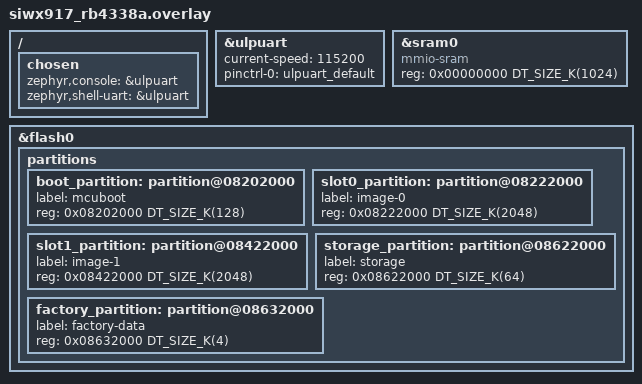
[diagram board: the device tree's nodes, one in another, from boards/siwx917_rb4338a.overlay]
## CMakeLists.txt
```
#
# Copyright (c) 2023-2024 Project CHIP Authors
#
# Licensed under the Apache License, Version 2.0 (the "License");
# you may not use this file except in compliance with the License.
# You may obtain a copy of the License at
#
# http://www.apache.org/licenses/LICENSE-2.0
#
# Unless required by applicable law or agreed to in writing, software
# distributed under the License is distributed on an "AS IS" BASIS,
# WITHOUT WARRANTIES OR CONDITIONS OF ANY KIND, either express or implied.
# See the License for the specific language governing permissions and
# limitations under the License.
#
cmake_minimum_required(VERSION 3.13.1)

get_filename_component(CHIP_ROOT ${CMAKE_CURRENT_SOURCE_DIR}/third_party/connectedhomeip REALPATH)
get_filename_component(GEN_DIR ${CHIP_ROOT}/zzz_generated/ REALPATH)
get_filename_component(SILABS_PLATFORM_COMMON ${CHIP_ROOT}/examples/platform/silabs REALPATH)
get_filename_component(SILABS_LIGHTING_COMMON ${CHIP_ROOT}/examples/lighting-app/silabs REALPATH)
get_filename_component(ALL_CLUSTERS_COMMON_DIR ${CHIP_ROOT}/examples/all-clusters-app/all-clusters-common REALPATH)
#get_filename_component(EXAMPLE_PLATFORM_SILABS_COMMON_DIR ${CHIP_ROOT}/examples/platform/nxp/common REALPATH)
#get_filename_component(EXAMPLE_PLATFORM_SILABS_ZEPHYR_DIR ${CHIP_ROOT}/examples/platform/nxp/zephyr REALPATH)

list(APPEND ZEPHYR_EXTRA_MODULES ${CHIP_ROOT}/config/silabs)
find_package(Zephyr HINTS $ENV{ZEPHYR_BASE})

# -Wmaybe-uninitialized has too many false positives, including on std::optional
# and chip::Optional.  Make it nonfatal.
#
# See https://gcc.gnu.org/bugzilla/show_bug.cgi?id=80635
target_compile_options(app PRIVATE -Werror -Wno-error=maybe-uninitialized)
target_compile_options(app PRIVATE -Werror PRIVATE -Wno-error=format)

project(matter-silabs-light)

include(${CHIP_ROOT}/config/silabs/app/enable-gnu-std.cmake)
include(${CHIP_ROOT}/src/app/chip_data_model.cmake)

target_include_directories(app
    PRIVATE
    include
    ${LAUNDRY_WASHER_SILABS_COMMON_DIR}/Zephyr/include
    ${ALL_CLUSTERS_COMMON_DIR}/include
    ${GEN_DIR}/app-common
    ${GEN_DIR}/all-clusters-app
    ${EXAMPLE_PLATFORM_SILABS_COMMON_DIR}/device_manager/include
    ${EXAMPLE_PLATFORM_SILABS_COMMON_DIR}/icd/include
    ${EXAMPLE_PLATFORM_SILABS_COMMON_DIR}/device_callbacks/include
    ${EXAMPLE_PLATFORM_SILABS_COMMON_DIR}/factory_data/include
    ${EXAMPLE_PLATFORM_SILABS_COMMON_DIR}/app_task/include
)

target_sources(app
    PRIVATE
    ${SILABS_PLATFORM_COMMON}/zephyr/src/main.cpp
    # ${LAUNDRY_WASHER_SILABS_COMMON_DIR}/main/AppTask.cpp
    # ${EXAMPLE_PLATFORM_SILABS_COMMON_DIR}/device_manager/source/CHIPDeviceManager.cpp
    # ${LAUNDRY_WASHER_SILABS_COMMON_DIR}/main/DeviceCallbacks.cpp
    # ${EXAMPLE_PLATFORM_SILABS_COMMON_DIR}/device_callbacks/source/CommonDeviceCallbacks.cpp
    # ${LAUNDRY_WASHER_SILABS_COMMON_DIR}/main/ZclCallbacks.cpp
    # ${ALL_CLUSTERS_COMMON_DIR}/src/binding-handler.cpp
    # ${EXAMPLE_PLATFORM_SILABS_COMMON_DIR}/app_task/source/AppTaskBase.cpp
    # ${EXAMPLE_PLATFORM_SILABS_COMMON_DIR}/app_task/source/AppTaskZephyr.cpp
    # ${EXAMPLE_PLATFORM_SILABS_ZEPHYR_DIR}/factory_data/source/AppFactoryDataExample.cpp
)

target_compile_definitions(app PUBLIC
    "EXTERNAL_FACTORY_DATA_PROVIDER_IMPL_HEADER=\"platform/nxp/zephyr/FactoryDataProviderImpl.h\""
)

# TODO MATTER-4291
if(CONFIG_CHIP_OTA_REQUESTOR)
    # target_sources(app PRIVATE
    #                 ${EXAMPLE_PLATFORM_SILABS_COMMON_DIR}/ota_requestor/source/OTARequestorInitiatorCommon.cpp
    #                 ${EXAMPLE_PLATFORM_SILABS_COMMON_DIR}/ota_requestor/source/OTARequestorInitiatorZephyr.cpp
    # )
    # target_include_directories(app PRIVATE
    #                 ${EXAMPLE_PLATFORM_SILABS_COMMON_DIR}/ota_requestor/include/
    # )
endif()

if(CONFIG_CHIP_WIFI)
  chip_configure_data_model(app
      ZAP_FILE ${SILABS_LIGHTING_COMMON}/data_model/lighting-wifi-app.zap
  )
else()
  chip_configure_data_model(app
      ZAP_FILE ${SILABS_LIGHTING_COMMON}/data_model/lighting-thread-app.zap
  )
endif()

if(CONFIG_CHIP_LIB_SHELL)
    target_compile_definitions(app PRIVATE ENABLE_CHIP_SHELL)
    target_include_directories(app PRIVATE 
                               ${CHIP_ROOT}/examples/shell/shell_common/include
                               ${EXAMPLE_PLATFORM_SILABS_COMMON_DIR}/matter_cli/include
    )
    target_sources(app PRIVATE
                   ${EXAMPLE_PLATFORM_SILABS_COMMON_DIR}/matter_cli/source/AppCLIBase.cpp
                   ${EXAMPLE_PLATFORM_SILABS_COMMON_DIR}/matter_cli/source/AppCLIZephyr.cpp
                   ${CHIP_ROOT}/examples/shell/shell_common/cmd_misc.cpp
                   ${CHIP_ROOT}/examples/shell/shell_common/cmd_otcli.cpp
                   ${CHIP_ROOT}/examples/shell/shell_common/cmd_server.cpp
    )
endif()

# TODO MATTER-4291
# target_sources(app
#     PRIVATE
#     ${ALL_CLUSTERS_COMMON_DIR}/src/smco-stub.cpp
#     ${ALL_CLUSTERS_COMMON_DIR}/src/bridged-actions-stub.cpp
#     # ${ALL_CLUSTERS_COMMON_DIR}/src/static-supported-temperature-levels.cpp
#     # ${ALL_CLUSTERS_COMMON_DIR}/src/laundry-washer-controls-delegate-impl.cpp
#     # ${ALL_CLUSTERS_COMMON_DIR}/src/operational-state-delegate-impl.cpp
# )
```

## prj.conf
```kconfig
#
#    Copyright (c) 2022 Project CHIP Authors
#
#    Licensed under the Apache License, Version 2.0 (the "License");
#    you may not use this file except in compliance with the License.
#    You may obtain a copy of the License at
#
#        http://www.apache.org/licenses/LICENSE-2.0
#
#    Unless required by applicable law or agreed to in writing, software
#    distributed under the License is distributed on an "AS IS" BASIS,
#    WITHOUT WARRANTIES OR CONDITIONS OF ANY KIND, either express or implied.
#    See the License for the specific language governing permissions and
#    limitations under the License.
#

# This sample uses Kconfig.defaults to set options common for all
# samples. This file should contain only options specific for this sample
# or overrides of default values.

# Enable CHIP
CONFIG_CHIP=y
CONFIG_CHIP_PROJECT_CONFIG="include/CHIPProjectConfig.h"
# 32773 == 0x8005 (example lighting-app)
CONFIG_CHIP_DEVICE_PRODUCT_ID=32773
CONFIG_STD_CPP17=y

CONFIG_GPIO=y

# Enable Matter extended announcement and increase duration to 1 hour.
CONFIG_CHIP_BLE_EXT_ADVERTISING=y
CONFIG_CHIP_BLE_ADVERTISING_DURATION=60

# Add support for LEDs and buttons on Nordic development kits
# Add support for LEDs and buttons on Silabs development kits
# TODO MATTER-4291
#CONFIG_PWM=y
# Add support for LCD on Silabs development kits
# General networking settings
CONFIG_NET_IF_MCAST_IPV6_ADDR_COUNT=5

# Bluetooth Low Energy configuration
CONFIG_BT_DEVICE_NAME="MatterLight"


# Other settings
CONFIG_THREAD_NAME=y

# Reduce application size
CONFIG_USE_SEGGER_RTT=n
```

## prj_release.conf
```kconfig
#
#    Copyright (c) 2022 Project CHIP Authors
#
#    Licensed under the Apache License, Version 2.0 (the "License");
#    you may not use this file except in compliance with the License.
#    You may obtain a copy of the License at
#
#        http://www.apache.org/licenses/LICENSE-2.0
#
#    Unless required by applicable law or agreed to in writing, software
#    distributed under the License is distributed on an "AS IS" BASIS,
#    WITHOUT WARRANTIES OR CONDITIONS OF ANY KIND, either express or implied.
#    See the License for the specific language governing permissions and
#    limitations under the License.
#

# This sample uses Kconfig.defaults to set options common for all
# samples. This file should contain only options specific for this sample
# or overrides of default values.

# Enable CHIP
CONFIG_CHIP=y
CONFIG_CHIP_PROJECT_CONFIG="include/CHIPProjectConfig.h"
# 32773 == 0x8005 (example lighting-app)
CONFIG_CHIP_DEVICE_PRODUCT_ID=32773
CONFIG_STD_CPP17=y

# Enable Matter pairing automatically on application start.
CONFIG_CHIP_ENABLE_PAIRING_AUTOSTART=y

# Enable Matter extended announcement and increase duration to 1 hour.
CONFIG_CHIP_BLE_EXT_ADVERTISING=y
CONFIG_CHIP_BLE_ADVERTISING_DURATION=60

# Add support for LEDs and buttons on Silabs development kits
# TODO MATTER-4291
#CONFIG_PWM=y
# Add support for LCD on Silabs development kits

# General networking settings
CONFIG_NET_IF_MCAST_IPV6_ADDR_COUNT=14

# Bluetooth Low Energy configuration
CONFIG_BT_DEVICE_NAME="MatterLight"

# Stack size settings


# Disable all debug features
CONFIG_USE_SEGGER_RTT=n
CONFIG_SHELL=n
CONFIG_OPENTHREAD_SHELL=n
CONFIG_CONSOLE=n
CONFIG_UART_CONSOLE=n
CONFIG_SERIAL=n
CONFIG_LOG=n
CONFIG_LOG_MODE_MINIMAL=n
CONFIG_ASSERT_VERBOSE=n
CONFIG_ASSERT_NO_FILE_INFO=y
CONFIG_PRINTK=n
CONFIG_PRINTK_SYNC=n
CONFIG_BOOT_BANNER=n
```

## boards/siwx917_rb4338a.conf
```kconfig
#
#    Copyright (c) 2024 Project CHIP Authors
#
#    Licensed under the Apache License, Version 2.0 (the "License");
#    you may not use this file except in compliance with the License.
#    You may obtain a copy of the License at
#
#        http://www.apache.org/licenses/LICENSE-2.0
#
#    Unless required by applicable law or agreed to in writing, software
#    distributed under the License is distributed on an "AS IS" BASIS,
#    WITHOUT WARRANTIES OR CONDITIONS OF ANY KIND, either express or implied.
#    See the License for the specific language governing permissions and
#    limitations under the License.
#
```

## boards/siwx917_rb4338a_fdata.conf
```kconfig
#
#    Copyright (c) 2024 Project CHIP Authors
#
#    Licensed under the Apache License, Version 2.0 (the "License");
#    you may not use this file except in compliance with the License.
#    You may obtain a copy of the License at
#
#        http://www.apache.org/licenses/LICENSE-2.0
#
#    Unless required by applicable law or agreed to in writing, software
#    distributed under the License is distributed on an "AS IS" BASIS,
#    WITHOUT WARRANTIES OR CONDITIONS OF ANY KIND, either express or implied.
#    See the License for the specific language governing permissions and
#    limitations under the License.
#

# 0xA226
CONFIG_CHIP_DEVICE_PRODUCT_ID=41510 # TODO MATTER-4864
CONFIG_CHIP_DEVICE_PRODUCT_URL="tbd"
CONFIG_CHIP_DEVICE_PRODUCT_LABEL="siwg917"
CONFIG_CHIP_DEVICE_PART_NUMBER="siwg917"
```

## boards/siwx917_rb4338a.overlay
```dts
/*
 *    Copyright (c) 2024 Project CHIP Authors
 *    All rights reserved.
 *
 *    Licensed under the Apache License, Version 2.0 (the "License");
 *    you may not use this file except in compliance with the License.
 *    You may obtain a copy of the License at
 *
 *        http: //www.apache.org/licenses/LICENSE-2.0
 *
 *    Unless required by applicable law or agreed to in writing, software
 *    distributed under the License is distributed on an "AS IS" BASIS
 *    WITHOUT WARRANTIES OR CONDITIONS OF ANY KIND, either express or implied.
 *    See the License for the specific language governing permissions and
 *    limitations under the License.
 */

/ {
	chosen {
		zephyr,console = &ulpuart;
		zephyr,shell-uart = &ulpuart;
	};
};

&ulpuart {
	status = "okay";
	current-speed = <115200>;
	pinctrl-0 = <&ulpuart_default>;
	pinctrl-names = "default";
};

/* Matter required multiples partition
 * 1. Bootloader for OTA
 * 2. Code partition
 * 3. Persistent storage
 * 4. Factory settings (certificate and others)
 */

&sram0 {
	status = "okay";
	compatible = "mmio-sram";
	reg = <0x00000000 DT_SIZE_K(1024)>;
};

&flash0 {
	status = "okay";
	partitions {
		boot_partition: partition@08202000 {
			label = "mcuboot";
			reg = <0x08202000 DT_SIZE_K(128)>;
		};

		slot0_partition: partition@08222000 {
			label = "image-0";
			reg = <0x08222000 DT_SIZE_K(2048)>;
		};

		slot1_partition: partition@08422000 {
			label = "image-1";
			reg = <0x08422000 DT_SIZE_K(2048)>;
		};

		storage_partition: partition@08622000 {
			label = "storage";
			reg = <0x08622000 DT_SIZE_K(64)>;
		};

		factory_partition: partition@08632000 {
			label = "factory-data";
			reg = <0x08632000 DT_SIZE_K(4)>;
		};

	};

};
```

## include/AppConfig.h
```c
/*
 *
 *    Copyright (c) 2020 Project CHIP Authors
 *    Copyright (c) 2019 Google LLC.
 *    All rights reserved.
 *
 *    Licensed under the Apache License, Version 2.0 (the "License");
 *    you may not use this file except in compliance with the License.
 *    You may obtain a copy of the License at
 *
 *        http://www.apache.org/licenses/LICENSE-2.0
 *
 *    Unless required by applicable law or agreed to in writing, software
 *    distributed under the License is distributed on an "AS IS" BASIS,
 *    WITHOUT WARRANTIES OR CONDITIONS OF ANY KIND, either express or implied.
 *    See the License for the specific language governing permissions and
 *    limitations under the License.
 */

#pragma once

#include "silabs_utils.h"

// ---- Lighting Example App Config ----

#ifdef SL_CATALOG_ZIGBEE_ZCL_FRAMEWORK_CORE_PRESENT
#include "sl_cmp_config.h"
#ifdef SL_MATTER_ZIGBEE_CMP
#include "ZigbeeCMPConfig.h"
#elif defined(SL_MATTER_ZIGBEE_SEQUENTIAL)
#include "ZigbeeSequentialConfig.h"
#endif // SL_MATTER_ZIGBEE_CMP
#else
#define APP_TASK_NAME "Light"
#define BLE_DEV_NAME "SL-" APP_TASK_NAME

#define ON_DEMO_BITMAP                                                                                                             \
    0xff, 0xff, 0xff, 0xff, 0xff, 0xff, 0xff, 0xff, 0xff, 0xff, 0xff, 0xff, 0xff, 0xff, 0xff, 0xff, 0xff, 0xff, 0xff, 0x7f, 0xfc,  \
        0xff, 0xff, 0xff, 0xff, 0xff, 0xff, 0x7f, 0xfc, 0xff, 0xff, 0xff, 0xff, 0xff, 0xff, 0x7f, 0xfc, 0xff, 0xff, 0xff, 0xff,    \
        0xff, 0xff, 0x7f, 0xfc, 0xff, 0xff, 0xff, 0xff, 0xff, 0xff, 0x7f, 0xfc, 0xff, 0xff, 0xff, 0xff, 0xff, 0xff, 0x7f, 0xfc,    \
        0xff, 0xff, 0xff, 0xff, 0xff, 0xff, 0x7f, 0xfc, 0xff, 0xff, 0xff, 0xff, 0xcf, 0xff, 0xff, 0xff, 0xff, 0xf3, 0xff, 0xff,    \
        0x8f, 0xff, 0xff, 0xff, 0xff, 0xf1, 0xff, 0xff, 0x0f, 0xff, 0xff, 0xff, 0xff, 0xf0, 0xff, 0xff, 0x1f, 0xfe, 0x07, 0xe0,    \
        0x7f, 0xf8, 0xff, 0xff, 0x3f, 0xfc, 0x00, 0x00, 0x3f, 0xfc, 0xff, 0xff, 0x7f, 0x3c, 0xe0, 0x07, 0x3c, 0xfe, 0xff, 0xff,    \
        0xff, 0x1f, 0xfe, 0x7f, 0xf8, 0xff, 0xff, 0xff, 0xff, 0x0f, 0xff, 0xff, 0xf0, 0xff, 0xff, 0xff, 0xff, 0xc7, 0xff, 0xff,    \
        0xe3, 0xff, 0xff, 0xff, 0xff, 0xe3, 0xff, 0xff, 0xc7, 0xff, 0xff, 0xff, 0xff, 0xf1, 0xff, 0xff, 0x8f, 0xff, 0xff, 0xff,    \
        0xff, 0xf1, 0xff, 0xff, 0x8f, 0xff, 0xff, 0xff, 0xff, 0xf8, 0xff, 0xff, 0x1f, 0xff, 0xff, 0xff, 0x7f, 0xfc, 0xff, 0xff,    \
        0x3f, 0xfe, 0xff, 0xff, 0x7f, 0xfc, 0xff, 0xff, 0x3f, 0xfe, 0xff, 0xff, 0x7f, 0xfc, 0xff, 0xff, 0x3f, 0xfe, 0xff, 0xff,    \
        0x7f, 0xfe, 0xff, 0xff, 0x7f, 0xfe, 0xff, 0xff, 0x3f, 0xfe, 0xff, 0xff, 0x7f, 0xfc, 0xff, 0xff, 0x3f, 0xfe, 0xff, 0xff,    \
        0x7f, 0xfc, 0xff, 0x0f, 0x38, 0xfe, 0xff, 0xff, 0x7f, 0x1c, 0xf0, 0x0f, 0x38, 0xfe, 0x03, 0xc0, 0x7f, 0x1c, 0xf0, 0x0f,    \
        0x38, 0xfe, 0x27, 0xe9, 0x7f, 0x1c, 0xf0, 0xff, 0x3f, 0xfe, 0xff, 0xff, 0x7f, 0xfc, 0xff, 0xff, 0x3f, 0xfe, 0xff, 0xff,    \
        0x7f, 0xfc, 0xff, 0xff, 0x3f, 0xfe, 0xe7, 0xe7, 0x7f, 0xfc, 0xff, 0xff, 0x7f, 0xfe, 0xef, 0xf7, 0x7f, 0xfe, 0xff, 0xff,    \
        0x7f, 0xfc, 0xef, 0xf7, 0x3f, 0xfe, 0xff, 0xff, 0xff, 0xfc, 0xef, 0xf3, 0x3f, 0xff, 0xff, 0xff, 0xff, 0xf8, 0xcf, 0xf3,    \
        0x1f, 0xff, 0xff, 0xff, 0xff, 0xf8, 0xdf, 0xfb, 0x1f, 0xff, 0xff, 0xff, 0xff, 0xf1, 0xdf, 0xfb, 0x8f, 0xff, 0xff, 0xff,    \
        0xff, 0xe3, 0x9f, 0xf9, 0xc7, 0xff, 0xff, 0xff, 0xff, 0xc3, 0x9f, 0xf9, 0xc3, 0xff, 0xff, 0xff, 0xff, 0xc7, 0x9f, 0xfd,    \
        0xe3, 0xff, 0xff, 0xff, 0xff, 0x8f, 0xbf, 0xfd, 0xf1, 0xff, 0xff, 0xff, 0xff, 0x1f, 0x3f, 0xfc, 0xf8, 0xff, 0xff, 0xff,    \
        0xff, 0x3f, 0x3e, 0x7c, 0xfc, 0xff, 0xff, 0xff, 0xff, 0x7f, 0xfc, 0x3f, 0xfe, 0xff, 0xff, 0xff, 0xff, 0x7f, 0xfc, 0x3f,    \
        0xfe, 0xff, 0xff, 0xff, 0xff, 0xff, 0xf8, 0x1f, 0xff, 0xff, 0xff, 0xff, 0xff, 0xff, 0x00, 0x00, 0xff, 0xff, 0xff, 0xff,    \
        0xff, 0xff, 0x00, 0x00, 0xff, 0xff, 0xff, 0xff, 0xff, 0xff, 0xf8, 0x1f, 0xff, 0xff, 0xff, 0xff, 0xff, 0xff, 0xf8, 0x1f,    \
        0xff, 0xff, 0xff, 0xff, 0xff, 0xff, 0xf8, 0x1f, 0xff, 0xff, 0xff, 0xff, 0xff, 0xff, 0x00, 0x00, 0xff, 0xff, 0xff, 0xff,    \
        0xff, 0xff, 0x00, 0x00, 0xff, 0xff, 0xff, 0xff, 0xff, 0xff, 0xf8, 0x1f, 0xff, 0xff, 0xff, 0xff, 0xff, 0xff, 0xf1, 0x8f,    \
        0xff, 0xff, 0xff, 0xff, 0xff, 0xff, 0x01, 0x80, 0xff, 0xff, 0xff, 0xff, 0xff, 0xff, 0x03, 0xc0, 0xff, 0xff, 0xff, 0xff,    \
        0xff, 0xff, 0x3f, 0xfc, 0xff, 0xff, 0xff, 0xff, 0xff, 0xff, 0xff, 0xff, 0xff, 0xff, 0xff, 0xff, 0xff, 0xff, 0xff, 0xff,    \
        0xff, 0xff, 0xff, 0xff, 0xff, 0xff, 0xff, 0xff, 0xff, 0xff, 0xff

#define OFF_DEMO_BITMAP                                                                                                            \
    0xff, 0xff, 0xff, 0xff, 0xff, 0xff, 0xff, 0xff, 0xff, 0xff, 0xff, 0xff, 0xff, 0xff, 0xff, 0xff, 0xff, 0xff, 0xff, 0xff, 0xff,  \
        0xff, 0xff, 0xff, 0xff, 0xff, 0xff, 0xff, 0xff, 0xff, 0xff, 0xff, 0xff, 0xff, 0xff, 0xff, 0xff, 0xff, 0xff, 0xff, 0xff,    \
        0xff, 0xff, 0xff, 0xff, 0xff, 0xff, 0xff, 0xff, 0xff, 0xff, 0xff, 0xff, 0xff, 0xff, 0xff, 0xff, 0xff, 0xff, 0xff, 0xff,    \
        0xff, 0xff, 0xff, 0xff, 0xff, 0xff, 0xff, 0xff, 0xff, 0xff, 0xff, 0xff, 0xff, 0xff, 0xff, 0xff, 0xff, 0xff, 0xff, 0xff,    \
        0xff, 0xff, 0xff, 0xff, 0xff, 0xff, 0xff, 0xff, 0xff, 0xff, 0xff, 0xff, 0xff, 0xff, 0xff, 0xff, 0xff, 0xff, 0x07, 0xe0,    \
        0xff, 0xff, 0xff, 0xff, 0xff, 0xff, 0x00, 0x00, 0xff, 0xff, 0xff, 0xff, 0xff, 0x3f, 0xe0, 0x07, 0xfc, 0xff, 0xff, 0xff,    \
        0xff, 0x1f, 0xfe, 0x7f, 0xf8, 0xff, 0xff, 0xff, 0xff, 0x0f, 0xff, 0xff, 0xf0, 0xff, 0xff, 0xff, 0xff, 0xc7, 0xff, 0xff,    \
        0xe3, 0xff, 0xff, 0xff, 0xff, 0xe3, 0xff, 0xff, 0xc7, 0xff, 0xff, 0xff, 0xff, 0xf1, 0xff, 0xff, 0x8f, 0xff, 0xff, 0xff,    \
        0xff, 0xf1, 0xff, 0xff, 0x8f, 0xff, 0xff, 0xff, 0xff, 0xf8, 0xff, 0xff, 0x1f, 0xff, 0xff, 0xff, 0x7f, 0xfc, 0xff, 0xff,    \
        0x3f, 0xfe, 0xff, 0xff, 0x7f, 0xfc, 0xff, 0xff, 0x3f, 0xfe, 0xff, 0xff, 0x7f, 0xfc, 0xff, 0xff, 0x3f, 0xfe, 0xff, 0xff,    \
        0x7f, 0xfe, 0xff, 0xff, 0x7f, 0xfe, 0xff, 0xff, 0x3f, 0xfe, 0xff, 0xff, 0x7f, 0xfc, 0xff, 0xff, 0x3f, 0xfe, 0xff, 0xff,    \
        0x7f, 0xfc, 0xff, 0xff, 0x3f, 0xfe, 0xff, 0xff, 0x7f, 0xfc, 0xff, 0xff, 0x3f, 0xfe, 0xff, 0xff, 0x7f, 0xfc, 0xff, 0xff,    \
        0x3f, 0xfe, 0xff, 0xff, 0x7f, 0xfc, 0xff, 0xff, 0x3f, 0xfe, 0xff, 0xff, 0x7f, 0xfc, 0xff, 0xff, 0x3f, 0xfe, 0xff, 0xff,    \
        0x7f, 0xfc, 0xff, 0xff, 0x3f, 0xfe, 0xff, 0xff, 0x7f, 0xfc, 0xff, 0xff, 0x7f, 0xfe, 0xff, 0xff, 0x7f, 0xfe, 0xff, 0xff,    \
        0x7f, 0xfc, 0xff, 0xff, 0x3f, 0xfe, 0xff, 0xff, 0xff, 0xfc, 0xff, 0xff, 0x3f, 0xff, 0xff, 0xff, 0xff, 0xf8, 0xff, 0xff,    \
        0x1f, 0xff, 0xff, 0xff, 0xff, 0xf8, 0xff, 0xff, 0x1f, 0xff, 0xff, 0xff, 0xff, 0xf1, 0xff, 0xff, 0x8f, 0xff, 0xff, 0xff,    \
        0xff, 0xe3, 0xff, 0xff, 0xc7, 0xff, 0xff, 0xff, 0xff, 0xc3, 0xff, 0xff, 0xc3, 0xff, 0xff, 0xff, 0xff, 0xc7, 0xff, 0xff,    \
        0xe3, 0xff, 0xff, 0xff, 0xff, 0x8f, 0xff, 0xff, 0xf1, 0xff, 0xff, 0xff, 0xff, 0x1f, 0xff, 0xff, 0xf8, 0xff, 0xff, 0xff,    \
        0xff, 0x3f, 0xfe, 0x7f, 0xfc, 0xff, 0xff, 0xff, 0xff, 0x7f, 0xfc, 0x3f, 0xfe, 0xff, 0xff, 0xff, 0xff, 0x7f, 0xfc, 0x3f,    \
        0xfe, 0xff, 0xff, 0xff, 0xff, 0xff, 0xf8, 0x1f, 0xff, 0xff, 0xff, 0xff, 0xff, 0xff, 0x00, 0x00, 0xff, 0xff, 0xff, 0xff,    \
        0xff, 0xff, 0x00, 0x00, 0xff, 0xff, 0xff, 0xff, 0xff, 0xff, 0xf8, 0x1f, 0xff, 0xff, 0xff, 0xff, 0xff, 0xff, 0xf8, 0x1f,    \
        0xff, 0xff, 0xff, 0xff, 0xff, 0xff, 0xf8, 0x1f, 0xff, 0xff, 0xff, 0xff, 0xff, 0xff, 0x00, 0x00, 0xff, 0xff, 0xff, 0xff,    \
        0xff, 0xff, 0x00, 0x00, 0xff, 0xff, 0xff, 0xff, 0xff, 0xff, 0xf8, 0x1f, 0xff, 0xff, 0xff, 0xff, 0xff, 0xff, 0xf1, 0x8f,    \
        0xff, 0xff, 0xff, 0xff, 0xff, 0xff, 0x01, 0x80, 0xff, 0xff, 0xff, 0xff, 0xff, 0xff, 0x03, 0xc0, 0xff, 0xff, 0xff, 0xff,    \
        0xff, 0xff, 0x3f, 0xfc, 0xff, 0xff, 0xff, 0xff, 0xff, 0xff, 0xff, 0xff, 0xff, 0xff, 0xff, 0xff, 0xff, 0xff, 0xff, 0xff,    \
        0xff, 0xff, 0xff, 0xff, 0xff, 0xff, 0xff, 0xff, 0xff, 0xff, 0xff
#endif // SL_CATALOG_ZIGBEE_ZCL_FRAMEWORK_CORE_PRESENT

// Time it takes in ms for the simulated actuator to move from one
// state to another.
#define ACTUATOR_MOVEMENT_PERIOD_MS 10

#define LIGHT_ENDPOINT 1

// Application-defined error codes in the CHIP_ERROR space.
#define APP_ERROR_EVENT_QUEUE_FAILED CHIP_APPLICATION_ERROR(0x01)
#define APP_ERROR_CREATE_TASK_FAILED CHIP_APPLICATION_ERROR(0x02)
#define APP_ERROR_UNHANDLED_EVENT CHIP_APPLICATION_ERROR(0x03)
#define APP_ERROR_CREATE_TIMER_FAILED CHIP_APPLICATION_ERROR(0x04)
#define APP_ERROR_START_TIMER_FAILED CHIP_APPLICATION_ERROR(0x05)
#define APP_ERROR_STOP_TIMER_FAILED CHIP_APPLICATION_ERROR(0x06)
```

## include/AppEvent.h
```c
/*
 *
 *    Copyright (c) 2020 Project CHIP Authors
 *    Copyright (c) 2018 Nest Labs, Inc.
 *    All rights reserved.
 *
 *    Licensed under the Apache License, Version 2.0 (the "License");
 *    you may not use this file except in compliance with the License.
 *    You may obtain a copy of the License at
 *
 *        http://www.apache.org/licenses/LICENSE-2.0
 *
 *    Unless required by applicable law or agreed to in writing, software
 *    distributed under the License is distributed on an "AS IS" BASIS,
 *    WITHOUT WARRANTIES OR CONDITIONS OF ANY KIND, either express or implied.
 *    See the License for the specific language governing permissions and
 *    limitations under the License.
 */

#pragma once
#if (defined(SL_MATTER_RGB_LED_ENABLED) && SL_MATTER_RGB_LED_ENABLED == 1)
#include "RGBLEDWidget.h"
#endif //(defined(SL_MATTER_RGB_LED_ENABLED) && SL_MATTER_RGB_LED_ENABLED == 1)

<<<<<<< HEAD
#ifdef DISPLAY_ENABLED
#include "lcd.h"
#endif

struct AppEvent;
typedef void (*EventHandler)(AppEvent *);
=======
#include "BaseAppEvent.h"
>>>>>>> csa/v1.4.2-branch

struct AppEvent : public BaseAppEvent
{
    enum AppEventTypes
    {
<<<<<<< HEAD
        kEventType_Button = 0,
        kEventType_LCD,
        kEventType_Timer,
        kEventType_Light,
=======
        kEventType_Light = BaseAppEvent::kEventType_Max + 1,
>>>>>>> csa/v1.4.2-branch
        kEventType_Install,
    };

    union
    {
        struct
        {
            uint8_t Action;
<<<<<<< HEAD
        } ButtonEvent;
#ifdef DISPLAY_ENABLED
        struct
        {
            SilabsLCD::Screen_e screen;
        } LCDEvent;
#endif
        struct
        {
            void * Context;
        } TimerEvent;
=======
            int32_t Actor;
            uint8_t Value;
        } LightEvent;

#if (defined(SL_MATTER_RGB_LED_ENABLED) && SL_MATTER_RGB_LED_ENABLED == 1)
>>>>>>> csa/v1.4.2-branch
        struct
        {
            uint8_t Action;
            int32_t Actor;
            RGBLEDWidget::ColorData_t Value;
        } LightControlEvent;
#endif // (defined(SL_MATTER_RGB_LED_ENABLED) && SL_MATTER_RGB_LED_ENABLED == 1)
    };
};
```

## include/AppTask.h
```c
/*
 *
 *    Copyright (c) 2020 Project CHIP Authors
 *    Copyright (c) 2019 Google LLC.
 *    All rights reserved.
 *
 *    Licensed under the Apache License, Version 2.0 (the "License");
 *    you may not use this file except in compliance with the License.
 *    You may obtain a copy of the License at
 *
 *        http://www.apache.org/licenses/LICENSE-2.0
 *
 *    Unless required by applicable law or agreed to in writing, software
 *    distributed under the License is distributed on an "AS IS" BASIS,
 *    WITHOUT WARRANTIES OR CONDITIONS OF ANY KIND, either express or implied.
 *    See the License for the specific language governing permissions and
 *    limitations under the License.
 */

#pragma once

#include "BaseApplication.h"
#include <app/ConcreteAttributePath.h>
#include <app/clusters/on-off-server/on-off-server.h>
#include <cstdint>

#include <app/persistence/DeferredAttributePersistenceProvider.h>
#include <ble/Ble.h>
#include <cmsis_os2.h>
#include <lib/core/CHIPError.h>

struct AppEvent;

#if (defined(SL_MATTER_RGB_LED_ENABLED) && SL_MATTER_RGB_LED_ENABLED == 1)
enum ColorAction_t : uint8_t
{
    COLOR_ACTION_XY = 0,
    COLOR_ACTION_HSV,
    COLOR_ACTION_CT,
};
#endif

class AppTask : public BaseApplication
{

public:
    AppTask() = default;

    static AppTask & GetAppTask();

    /**
     * @brief AppTask task main loop function
     *
     * @param pvParameter FreeRTOS task parameter
     */
    static void AppTaskMain(void * pvParameter);

    CHIP_ERROR StartAppTask();

    /**
     * @brief Event handler when a button is pressed.
     *
     * @param button    APP_LIGHT_SWITCH or APP_FUNCTION_BUTTON
     * @param btnAction SL_SIMPLE_BUTTON_PRESSED, SL_SIMPLE_BUTTON_RELEASED or SL_SIMPLE_BUTTON_DISABLED
     */
    static void ButtonEventHandler(uint8_t button, uint8_t btnAction);

    static void OnTriggerOffWithEffect(OnOffEffect * effect);

    void DMPostAttributeChangeCallback(const chip::app::ConcreteAttributePath & attributePath, uint8_t type, uint16_t size,
                                       uint8_t * value);

    static void LightActionEventHandler(AppEvent * aEvent);

    static void LightTimerEventHandler(void * timerCbArg);

    static void DummyEventHandler(AppEvent * aEvent);

#if (defined(SL_MATTER_RGB_LED_ENABLED) && SL_MATTER_RGB_LED_ENABLED == 1)
    static void LightControlEventHandler(AppEvent * aEvent);
#endif

protected:
    CHIP_ERROR AppInit() override;
    CHIP_ERROR InitLight();

    static void UpdateOnOffClusterState(intptr_t context);
    chip::app::DeferredAttributePersistenceProvider * pDeferredAttributePersister = nullptr;
};
```

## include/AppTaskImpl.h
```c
/*
 *
 *    Copyright (c) 2020 Project CHIP Authors
 *    Copyright (c) 2019 Google LLC.
 *    All rights reserved.
 *
 *    Licensed under the Apache License, Version 2.0 (the "License");
 *    you may not use this file except in compliance with the License.
 *    You may obtain a copy of the License at
 *
 *        http://www.apache.org/licenses/LICENSE-2.0
 *
 *    Unless required by applicable law or agreed to in writing, software
 *    distributed under the License is distributed on an "AS IS" BASIS,
 *    WITHOUT WARRANTIES OR CONDITIONS OF ANY KIND, either express or implied.
 *    See the License for the specific language governing permissions and
 *    limitations under the License.
 */

#pragma once

#include "AppTask.h"
#include "CRTPHelpers.h"

/**
 * @brief CRTP override layer for `AppTask`.
 *
 * Each public entry point dispatches to a corresponding `Derived::*Impl()` hook.
 * The default `*Impl()` (declared private below) forwards to `AppTask`, so
 * `Derived` only needs to override the hooks whose behavior it wants to
 * customize.
 *
 * Customer code overrides these hooks in `CustomerAppTask`; see the app README
 * ("How to Override APIs").
 *
 * @tparam Derived The CRTP derived class (`CustomerAppTask`).
 */
template <typename Derived>
class AppTaskImpl : public AppTask
{
public:
    // Initialization hooks.
    CHIP_ERROR AppInit() override { CRTP_OPTIONAL_DISPATCH(AppTaskImpl, Derived, AppInitImpl); }

    CHIP_ERROR InitLight() { CRTP_OPTIONAL_DISPATCH(AppTaskImpl, Derived, InitLightImpl); }

    // External callbacks invoked outside the AppTask thread (e.g. button ISR, OnOff cluster).
    // Implementations typically post an event to the AppTask queue.
    static void ButtonEventHandler(uint8_t button, uint8_t btnAction)
    {
        CRTP_OPTIONAL_STATIC_DISPATCH(AppTaskImpl, Derived, ButtonEventHandlerImpl, button, btnAction);
    }

    static void OnTriggerOffWithEffect(OnOffEffect * effect)
    {
        CRTP_OPTIONAL_STATIC_DISPATCH(AppTaskImpl, Derived, OnTriggerOffWithEffectImpl, effect);
    }

    // Handlers invoked from AppTask, timer, or stack threads — see each method for the exact context.
    static void LightActionEventHandler(AppEvent * aEvent)
    {
        CRTP_OPTIONAL_STATIC_DISPATCH(AppTaskImpl, Derived, LightActionEventHandlerImpl, aEvent);
    }

    static void LightTimerEventHandler(void * timerCbArg)
    {
        CRTP_OPTIONAL_STATIC_DISPATCH(AppTaskImpl, Derived, LightTimerEventHandlerImpl, timerCbArg);
    }

#if (defined(SL_MATTER_RGB_LED_ENABLED) && SL_MATTER_RGB_LED_ENABLED == 1)
    static void LightControlEventHandler(AppEvent * aEvent)
    {
        CRTP_OPTIONAL_STATIC_DISPATCH(AppTaskImpl, Derived, LightControlEventHandlerImpl, aEvent);
    }
#endif

    void DMPostAttributeChangeCallback(const chip::app::ConcreteAttributePath & attributePath, uint8_t type, uint16_t size,
                                       uint8_t * value)
    {
        CRTP_OPTIONAL_VOID_DISPATCH(AppTaskImpl, Derived, DMPostAttributeChangeCallbackImpl, attributePath, type, size, value);
    }

    static void DummyEventHandler(AppEvent * aEvent)
    {
        CRTP_OPTIONAL_STATIC_DISPATCH(AppTaskImpl, Derived, DummyEventHandlerImpl, aEvent);
    }

private:
    friend Derived;

    /** Default implementations — override in Derived to customize. */

    // Initialization hooks (*Impl)
    CHIP_ERROR AppInitImpl() { return AppTask::AppInit(); }

    CHIP_ERROR InitLightImpl() { return AppTask::InitLight(); }

    // External callbacks (*Impl)
    void ButtonEventHandlerImpl(uint8_t button, uint8_t btnAction) { AppTask::ButtonEventHandler(button, btnAction); }

    void OnTriggerOffWithEffectImpl(OnOffEffect * effect) { AppTask::OnTriggerOffWithEffect(effect); }

    // Event / timer / data-model handlers (*Impl)
    void LightActionEventHandlerImpl(AppEvent * aEvent) { AppTask::LightActionEventHandler(aEvent); }

    void LightTimerEventHandlerImpl(void * timerCbArg) { AppTask::LightTimerEventHandler(timerCbArg); }

#if (defined(SL_MATTER_RGB_LED_ENABLED) && SL_MATTER_RGB_LED_ENABLED == 1)
    void LightControlEventHandlerImpl(AppEvent * aEvent) { AppTask::LightControlEventHandler(aEvent); }
#endif

    void DMPostAttributeChangeCallbackImpl(const chip::app::ConcreteAttributePath & attributePath, uint8_t type, uint16_t size,
                                           uint8_t * value)
    {
        AppTask::DMPostAttributeChangeCallback(attributePath, type, size, value);
    }

    void DummyEventHandlerImpl(AppEvent * aEvent) { AppTask::DummyEventHandler(aEvent); }
};
```

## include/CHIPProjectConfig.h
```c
/*
 *
 *    Copyright (c) 2020 Project CHIP Authors
 *    Copyright (c) 2019 Google LLC.
 *    All rights reserved.
 *
 *    Licensed under the Apache License, Version 2.0 (the "License");
 *    you may not use this file except in compliance with the License.
 *    You may obtain a copy of the License at
 *
 *        http://www.apache.org/licenses/LICENSE-2.0
 *
 *    Unless required by applicable law or agreed to in writing, software
 *    distributed under the License is distributed on an "AS IS" BASIS,
 *    WITHOUT WARRANTIES OR CONDITIONS OF ANY KIND, either express or implied.
 *    See the License for the specific language governing permissions and
 *    limitations under the License.
 */

/**
 *    @file
 *          Example project configuration file for CHIP.
 *
 *          This is a place to put application or project-specific overrides
 *          to the default configuration values for general CHIP features.
 *
 */

#pragma once

// Use a default pairing code if one hasn't been provisioned in flash.
#ifndef CHIP_DEVICE_CONFIG_USE_TEST_SETUP_PIN_CODE
#define CHIP_DEVICE_CONFIG_USE_TEST_SETUP_PIN_CODE 20202021
#endif

#ifndef CHIP_DEVICE_CONFIG_USE_TEST_SETUP_DISCRIMINATOR
#define CHIP_DEVICE_CONFIG_USE_TEST_SETUP_DISCRIMINATOR 0xF00
#endif

#ifdef __ZEPHYR__
#define CHIP_DEVICE_CONFIG_CHIP_TASK_NAME "Matter"
#define CHIP_DEVICE_CONFIG_CHIP_TASK_PRIORITY (K_PRIO_PREEMPT(10))
#define CHIP_DEVICE_CONFIG_CHIP_TASK_STACK_SIZE 10240
#endif

// For convenience, Chip Security Test Mode can be enabled and the
// requirement for authentication in various protocols can be disabled.
//
//    WARNING: These options make it possible to circumvent basic Chip security functionality,
//    including message encryption. Because of this they MUST NEVER BE ENABLED IN PRODUCTION BUILDS.
//
#define CHIP_CONFIG_SECURITY_TEST_MODE 0

/**
 * CHIP_DEVICE_CONFIG_DEVICE_VENDOR_ID
 *
 * 0xFFF1: Test vendor
 */
#define CHIP_DEVICE_CONFIG_DEVICE_VENDOR_ID 0xFFF1

/**
 * CHIP_DEVICE_CONFIG_DEVICE_PRODUCT_ID
 *
 * 0x8005: example lighting app
 */
#define CHIP_DEVICE_CONFIG_DEVICE_PRODUCT_ID 0x8005

/**
 * CHIP_DEVICE_CONFIG_ENABLE_CHIPOBLE
 *
 * Enable support for Chip-over-BLE (CHIPoBLE).
 */
#define CHIP_DEVICE_CONFIG_ENABLE_CHIPOBLE 1

/**
 * CHIP_DEVICE_CONFIG_TEST_SERIAL_NUMBER
 *
 * Enables the use of a hard-coded default serial number if none
 * is found in Chip NV storage.
 */
#define CHIP_DEVICE_CONFIG_TEST_SERIAL_NUMBER "TEST_SN"

/**
 * CHIP_DEVICE_CONFIG_EVENT_LOGGING_UTC_TIMESTAMPS
 *
 * Enable recording UTC timestamps.
 */
#define CHIP_DEVICE_CONFIG_EVENT_LOGGING_UTC_TIMESTAMPS 1

/**
 * CHIP_DEVICE_CONFIG_EVENT_LOGGING_DEBUG_BUFFER_SIZE
 *
 * A size, in bytes, of the individual debug event logging buffer.
 */
#define CHIP_DEVICE_CONFIG_EVENT_LOGGING_DEBUG_BUFFER_SIZE (512)

/**
 *  @def CHIP_CONFIG_MRP_LOCAL_ACTIVE_RETRY_INTERVAL
 *
 *  @brief
 *    Active retransmit interval, or time to wait before retransmission after
 *    subsequent failures in milliseconds.
 *
 *  This is the default value, that might be adjusted by end device depending on its
 *  needs (e.g. sleeping period) using Service Discovery TXT record CRA key.
 *
 */
#define CHIP_CONFIG_MRP_LOCAL_ACTIVE_RETRY_INTERVAL (2000_ms32)

// This is a temporary setting to use the CustomerAppTask for the apps which are not upgraded to the new architecture.
#define CHIP_SILABS_APP_USE_COMMON_APP_TASK
```

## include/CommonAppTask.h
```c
/*
 *
 *    Copyright (c) 2020 Project CHIP Authors
 *    Copyright (c) 2019 Google LLC.
 *    All rights reserved.
 *
 *    Licensed under the Apache License, Version 2.0 (the "License");
 *    you may not use this file except in compliance with the License.
 *    You may obtain a copy of the License at
 *
 *        http://www.apache.org/licenses/LICENSE-2.0
 *
 *    Unless required by applicable law or agreed to in writing, software
 *    distributed under the License is distributed on an "AS IS" BASIS,
 *    WITHOUT WARRANTIES OR CONDITIONS OF ANY KIND, either express or implied.
 *    See the License for the specific language governing permissions and
 *    limitations under the License.
 */

#pragma once

#include "AppTaskImpl.h"

/**
 * @brief Minimal AppTaskImpl-derived class that overrides only ButtonEventHandler.
 *
 * Use this as a template when you need custom button behavior; override
 * ButtonEventHandlerImpl() and add AppInitImpl() / GetAppTask() / sAppTask
 * as required by the CRTP base.
 */
class CommonAppTask : public AppTaskImpl<CommonAppTask>
{
public:
    static CommonAppTask & GetAppTask() { return sAppTask; }

private:
    friend class AppTaskImpl<CommonAppTask>;

    CHIP_ERROR AppInitImpl();

    static CommonAppTask sAppTask;
};
```

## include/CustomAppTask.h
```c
/*
 *
 *    Copyright (c) 2020 Project CHIP Authors
 *    Copyright (c) 2019 Google LLC.
 *    All rights reserved.
 *
 *    Licensed under the Apache License, Version 2.0 (the "License");
 *    you may not use this file except in compliance with the License.
 *    You may obtain a copy of the License at
 *
 *        http://www.apache.org/licenses/LICENSE-2.0
 *
 *    Unless required by applicable law or agreed to in writing, software
 *    distributed under the License is distributed on an "AS IS" BASIS,
 *    WITHOUT WARRANTIES OR CONDITIONS OF ANY KIND, either express or implied.
 *    See the License for the specific language governing permissions and
 *    limitations under the License.
 */

#pragma once

#include "AppTaskImpl.h"

/**
 * @brief Minimal AppTaskImpl-derived class that overrides only ButtonEventHandler.
 *
 * Use this as a template when you need custom button behavior; override
 * ButtonEventHandlerImpl() and add AppInitImpl() / GetAppTask() / sAppTask
 * as required by the CRTP base.
 */
class CustomAppTask : public AppTaskImpl<CustomAppTask>
{
public:
    static CustomAppTask & GetAppTask() { return sAppTask; }

private:
    friend class AppTaskImpl;

    static CustomAppTask sAppTask;
};
```

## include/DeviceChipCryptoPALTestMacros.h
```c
/*
 *    Copyright (c) 2026 Project CHIP Authors
 *
 *    Licensed under the Apache License, Version 2.0 (the "License");
 *    you may not use this file except in compliance with the License.
 *    You may obtain a copy of the License at
 *
 *        http://www.apache.org/licenses/LICENSE-2.0
 *
 *    Unless required by applicable law or agreed to in writing, software
 *    distributed under the License is distributed on an "AS IS" BASIS,
 *    WITHOUT WARRANTIES OR CONDITIONS OF ANY KIND, either express or implied.
 *    See the License for the specific language governing permissions and
 *    limitations under the License.
 */

#pragma once

#include <cstring>

#include <lib/core/CHIPError.h>
#include <lib/support/logging/CHIPLogging.h>

namespace DeviceChipCryptoPALTestDetail {
inline bool & FailureFlag()
{
    static bool failed = false;
    return failed;
}
} // namespace DeviceChipCryptoPALTestDetail

#define TEST_F(suite, name) static CHIP_ERROR DeviceCryptoTest_##name()

#define DEVICE_TEST_FAIL()                                                                                                         \
    do                                                                                                                             \
    {                                                                                                                              \
        ChipLogError(Crypto, "Device crypto test failed at %s:%d", __FILE__ + 119, __LINE__);                                      \
        DeviceChipCryptoPALTestDetail::FailureFlag() = true;                                                                       \
    } while (0)

#define DEVICE_TEST_RESULT() (DeviceChipCryptoPALTestDetail::FailureFlag() ? CHIP_ERROR_INTERNAL : CHIP_NO_ERROR)

#define EXPECT_EQ(a, b)                                                                                                            \
    do                                                                                                                             \
    {                                                                                                                              \
        if (!((a) == (b)))                                                                                                         \
        {                                                                                                                          \
            DEVICE_TEST_FAIL();                                                                                                    \
        }                                                                                                                          \
    } while (0)

#define EXPECT_NE(a, b)                                                                                                            \
    do                                                                                                                             \
    {                                                                                                                              \
        if (!((a) != (b)))                                                                                                         \
        {                                                                                                                          \
            DEVICE_TEST_FAIL();                                                                                                    \
        }                                                                                                                          \
    } while (0)

#define EXPECT_TRUE(x)                                                                                                             \
    do                                                                                                                             \
    {                                                                                                                              \
        if (!(x))                                                                                                                  \
        {                                                                                                                          \
            DEVICE_TEST_FAIL();                                                                                                    \
        }                                                                                                                          \
    } while (0)

#define EXPECT_SUCCESS(err) EXPECT_EQ((err), CHIP_NO_ERROR)

#define EXPECT_LE(a, b)                                                                                                            \
    do                                                                                                                             \
    {                                                                                                                              \
        if (!((a) <= (b)))                                                                                                         \
        {                                                                                                                          \
            DEVICE_TEST_FAIL();                                                                                                    \
        }                                                                                                                          \
    } while (0)

#define EXPECT_GT(a, b)                                                                                                            \
    do                                                                                                                             \
    {                                                                                                                              \
        if (!((a) > (b)))                                                                                                          \
        {                                                                                                                          \
            DEVICE_TEST_FAIL();                                                                                                    \
        }                                                                                                                          \
    } while (0)

#define ASSERT_EQ(a, b) EXPECT_EQ(a, b)
#define ASSERT_TRUE(x) EXPECT_TRUE(x)
#define ASSERT_SUCCESS(err) EXPECT_SUCCESS(err)
#define ASSERT_GT(a, b) EXPECT_GT(a, b)

#define EXPECT_FALSE(x) EXPECT_TRUE(!(x))

#define ADD_FAILURE() DEVICE_TEST_FAIL()

#define GTEST_SKIP() return CHIP_NO_ERROR

#define EXPECT_STREQ(a, b)                                                                                                         \
    do                                                                                                                             \
    {                                                                                                                              \
        if (strcmp((a), (b)) != 0)                                                                                                 \
        {                                                                                                                          \
            DEVICE_TEST_FAIL();                                                                                                    \
        }                                                                                                                          \
    } while (0)
```

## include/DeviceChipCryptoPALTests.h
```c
/*
 *    Copyright (c) 2026 Project CHIP Authors
 *
 *    Licensed under the Apache License, Version 2.0 (the "License");
 *    you may not use this file except in compliance with the License.
 *    You may obtain a copy of the License at
 *
 *        http://www.apache.org/licenses/LICENSE-2.0
 *
 *    Unless required by applicable law or agreed to in writing, software
 *    distributed under the License is distributed on an "AS IS" BASIS,
 *    WITHOUT WARRANTIES OR CONDITIONS OF ANY KIND, either express or implied.
 *    See the License for the specific language governing permissions and
 *    limitations under the License.
 */

#pragma once

#include <lib/core/CHIPError.h>

CHIP_ERROR RunAllDeviceChipCryptoPALTests();

// Subset of TestChipCryptoPAL tests covering crypto used by PASESession (PBKDF2, SPAKE2P, SHA256, HKDF, DRBG).
CHIP_ERROR RunPASEChipCryptoPALTests();
```

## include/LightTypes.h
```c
/*
 *
 *    Copyright (c) 2020 Project CHIP Authors
 *    Copyright (c) 2019 Google LLC.
 *    All rights reserved.
 *
 *    Licensed under the Apache License, Version 2.0 (the "License");
 *    you may not use this file except in compliance with the License.
 *    You may obtain a copy of the License at
 *
 *        http://www.apache.org/licenses/LICENSE-2.0
 *
 *    Unless required by applicable law or agreed to in writing, software
 *    distributed under the License is distributed on an "AS IS" BASIS,
 *    WITHOUT WARRANTIES OR CONDITIONS OF ANY KIND, either express or implied.
 *    See the License for the specific language governing permissions and
 *    limitations under the License.
 */

#pragma once

#include <stdint.h>

namespace LightingManager {

enum Action_t
{
    ON_ACTION = 0,
    OFF_ACTION,
    LEVEL_ACTION,
    COLOR_ACTION_HSV,
    COLOR_ACTION_CT,
    COLOR_ACTION_XY,

    INVALID_ACTION
};

enum State_t
{
    kState_OffInitiated = 0,
    kState_OffCompleted,
    kState_OnInitiated,
    kState_OnCompleted,
};

} // namespace LightingManager
```

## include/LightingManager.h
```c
/*
 *
 *    Copyright (c) 2019 Google LLC.
 *    All rights reserved.
 *
 *    Licensed under the Apache License, Version 2.0 (the "License");
 *    you may not use this file except in compliance with the License.
 *    You may obtain a copy of the License at
 *
 *        http://www.apache.org/licenses/LICENSE-2.0
 *
 *    Unless required by applicable law or agreed to in writing, software
 *    distributed under the License is distributed on an "AS IS" BASIS,
 *    WITHOUT WARRANTIES OR CONDITIONS OF ANY KIND, either express or implied.
 *    See the License for the specific language governing permissions and
 *    limitations under the License.
 */

#pragma once

#include <stdbool.h>
#include <stdint.h>

#include "AppEvent.h"

#include <app-common/zap-generated/ids/Attributes.h>
#include <app/clusters/on-off-server/on-off-server.h>
#include <cmsis_os2.h>
#include <lib/core/CHIPError.h>

class LightingManager
{
public:
    enum Action_t
    {
        ON_ACTION = 0,
        OFF_ACTION,
        LEVEL_ACTION,
        COLOR_ACTION_HSV,
        COLOR_ACTION_CT,
        COLOR_ACTION_XY,

        INVALID_ACTION
    } Action;

    enum State_t
    {
        kState_OffInitiated = 0,
        kState_OffCompleted,
        kState_OnInitiated,
        kState_OnCompleted,
    } State;

    CHIP_ERROR Init();
    bool IsLightOn();
    void EnableAutoTurnOff(bool aOn);
    void SetAutoTurnOffDuration(uint32_t aDurationInSecs);
    bool IsActionInProgress();
    bool InitiateAction(int32_t aActor, Action_t aAction, uint8_t * aValue);
#if (defined(SL_MATTER_RGB_LED_ENABLED) && SL_MATTER_RGB_LED_ENABLED == 1)
    bool InitiateLightCtrlAction(int32_t aActor, Action_t aAction, uint32_t aAttributeId, uint8_t * value);
#endif // (defined(SL_MATTER_RGB_LED_ENABLED) && SL_MATTER_RGB_LED_ENABLED)
    typedef void (*Callback_fn_initiated)(Action_t, int32_t aActor, uint8_t * value);
    typedef void (*Callback_fn_completed)(Action_t);
    void SetCallbacks(Callback_fn_initiated aActionInitiated_CB, Callback_fn_completed aActionCompleted_CB);

    static void OnTriggerOffWithEffect(OnOffEffect * effect);

private:
    friend LightingManager & LightMgr(void);
    State_t mState;

#if (defined(SL_MATTER_RGB_LED_ENABLED) && SL_MATTER_RGB_LED_ENABLED == 1)
    uint8_t mCurrentLevel      = 254; // 0xFE = default
    uint8_t mCurrentHue        = 0;
    uint8_t mCurrentSaturation = 0;
    uint16_t mCurrentX;
    uint16_t mCurrentY;
    uint16_t mCurrentCTMireds;
#endif // (defined(SL_MATTER_RGB_LED_ENABLED) && SL_MATTER_RGB_LED_ENABLED == 1)

    Callback_fn_initiated mActionInitiated_CB;
    Callback_fn_completed mActionCompleted_CB;

    bool mAutoTurnOff;
    uint32_t mAutoTurnOffDuration;
    bool mAutoTurnOffTimerArmed;
    bool mOffEffectArmed;
    osTimerId_t mLightTimer;

    void CancelTimer(void);
    void StartTimer(uint32_t aTimeoutMs);

    static void TimerEventHandler(void * timerCbArg);
    static void AutoTurnOffTimerEventHandler(AppEvent * aEvent);
    static void ActuatorMovementTimerEventHandler(AppEvent * aEvent);
    static void OffEffectTimerEventHandler(AppEvent * aEvent);

    static LightingManager sLight;
};

inline LightingManager & LightMgr(void)
{
    return LightingManager::sLight;
}
```
